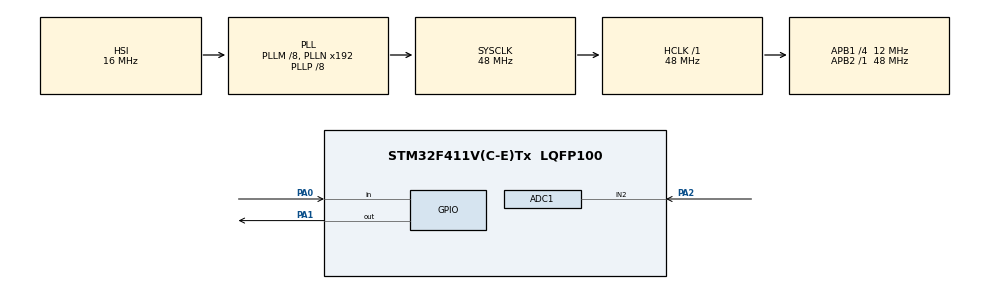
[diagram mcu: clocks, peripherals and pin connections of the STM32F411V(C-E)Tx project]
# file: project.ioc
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ADC1.Channel-0\#ChannelRegularConversion=ADC_CHANNEL_2
ADC1.ContinuousConvMode=ENABLE
ADC1.NbrOfConversionFlag=1
ADC1.Rank-0\#ChannelRegularConversion=1
ADC1.SamplingTime-0\#ChannelRegularConversion=ADC_SAMPLETIME_3CYCLES
ADC1.master=1
Mcu.Family=STM32F4
Mcu.Name=STM32F411V(C-E)Tx
Mcu.Package=LQFP100
NVIC.PriorityGroup=NVIC_PRIORITYGROUP_0
PA0-WKUP.Signal=GPIO_Input
PA1.Signal=GPIO_Output
PA2.Signal=ADCx_IN2
ProjectManager.HeapSize=0x200
ProjectManager.StackSize=0x400
ProjectManager.TargetToolchain=STM32CubeIDE
RCC.48MHZClocksFreq_Value=48000000
RCC.AHBFreq_Value=48000000
RCC.APB1CLKDivider=RCC_HCLK_DIV4
RCC.APB1Freq_Value=12000000
RCC.APB1TimFreq_Value=24000000
RCC.APB2Freq_Value=48000000
RCC.APB2TimFreq_Value=48000000
RCC.CortexFreq_Value=48000000
RCC.HCLKFreq_Value=48000000
RCC.HSE_VALUE=8000000
RCC.HSI_VALUE=16000000
RCC.LSE_VALUE=32768
RCC.PLLI2SM=5
RCC.PLLI2SN=200
RCC.PLLM=8
RCC.PLLP=RCC_PLLP_DIV8
RCC.PLLQ=8
RCC.SYSCLKFreq_VALUE=48000000
RCC.SYSCLKSource=RCC_SYSCLKSOURCE_PLLCLK
RCC.VCOOutputFreq_Value=384000000
SH.ADCx_IN2.0=ADC1_IN2,IN2
board=STM32F411E-DISCO

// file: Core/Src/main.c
/* USER CODE BEGIN Header */
/**
  ******************************************************************************
  * @file           : main.c
  * @brief          : Control simple de láser con botón
  ******************************************************************************
  */
/* USER CODE END Header */
#include "main.h"

/* USER CODE BEGIN PV */
volatile uint8_t disparo=0; //estado de disparo
volatile uint32_t valor_adc=0; //valor detectado
volatile uint8_t detectado=0; //estado de deteccion

//variables para la conversion y para el acceso directo a memoria del ldr
ADC_HandleTypeDef hadc1;
DMA_HandleTypeDef hdma_adc1;

/* USER CODE END PV */

void SystemClock_Config(void);
static void MX_GPIO_Init(void);
static void MX_ADC1_Init(void);

/* USER CODE BEGIN 0 */
void HAL_GPIO_EXTI_Callback(uint16_t GPIO_Pin){
	if (GPIO_Pin == GPIO_PIN_0){
		if (HAL_GPIO_ReadPin(GPIOA, GPIO_PIN_0) == 1){
			disparo = 1;
	        HAL_GPIO_WritePin(GPIOA, GPIO_PIN_1, GPIO_PIN_SET);
	    }
	    else{
	    	disparo = 0;
	        HAL_GPIO_WritePin(GPIOA, GPIO_PIN_1, GPIO_PIN_RESET);
	    }
	}
}

//}

/* USER CODE END 0 */

int main(void)
{

  /* MCU Configuration--------------------------------------------------------*/

  /* Reset of all peripherals, Initializes the Flash interface and the Systick. */
  HAL_Init();

  /* Configure the system clock */
  SystemClock_Config();

  /* Initialize all configured peripherals */
  MX_GPIO_Init();
  MX_ADC1_Init();
  /* USER CODE BEGIN 2 */

  //arranco el ADC
  HAL_ADC_Start_DMA(&hadc1, (uint32_t*)&valor_adc, 1);
  /* USER CODE END 2 */

  /* Infinite loop */
  while (1)
  {

    /* USER CODE BEGIN 3 */
	  if (disparo == 1)
	  {

	      if (valor_adc > 1500)
	      {
	          detectado = 1;
	      }
	      else
	      {
	          detectado = 0;
	      }
	  }
	  else
	  {
	      detectado = 0;
	  }
  /* USER CODE END 3 */
  }
}

void SystemClock_Config(void)
{
  RCC_OscInitTypeDef RCC_OscInitStruct = {0};
  RCC_ClkInitTypeDef RCC_ClkInitStruct = {0};

  /** Configure the main internal regulator output voltage
  */
  __HAL_RCC_PWR_CLK_ENABLE();
  __HAL_PWR_VOLTAGESCALING_CONFIG(PWR_REGULATOR_VOLTAGE_SCALE1);

  /** Initializes the RCC Oscillators according to the specified parameters
  * in the RCC_OscInitTypeDef structure.
  */
  RCC_OscInitStruct.OscillatorType = RCC_OSCILLATORTYPE_HSI;
  RCC_OscInitStruct.HSIState = RCC_HSI_ON;
  RCC_OscInitStruct.HSICalibrationValue = RCC_HSICALIBRATION_DEFAULT;
  RCC_OscInitStruct.PLL.PLLState = RCC_PLL_ON;
  RCC_OscInitStruct.PLL.PLLSource = RCC_PLLSOURCE_HSI;
  RCC_OscInitStruct.PLL.PLLM = 8;
  RCC_OscInitStruct.PLL.PLLN = 192;
  RCC_OscInitStruct.PLL.PLLP = RCC_PLLP_DIV8;
  RCC_OscInitStruct.PLL.PLLQ = 8;
  if (HAL_RCC_OscConfig(&RCC_OscInitStruct) != HAL_OK)
  {
    Error_Handler();
  }

  /** Initializes the CPU, AHB and APB buses clocks
  */
  RCC_ClkInitStruct.ClockType = RCC_CLOCKTYPE_HCLK|RCC_CLOCKTYPE_SYSCLK
                              |RCC_CLOCKTYPE_PCLK1|RCC_CLOCKTYPE_PCLK2;
  RCC_ClkInitStruct.SYSCLKSource = RCC_SYSCLKSOURCE_PLLCLK;
  RCC_ClkInitStruct.AHBCLKDivider = RCC_SYSCLK_DIV1;
  RCC_ClkInitStruct.APB1CLKDivider = RCC_HCLK_DIV4;
  RCC_ClkInitStruct.APB2CLKDivider = RCC_HCLK_DIV1;

  if (HAL_RCC_ClockConfig(&RCC_ClkInitStruct, FLASH_LATENCY_1) != HAL_OK)
  {
    Error_Handler();
  }
}

static void MX_ADC1_Init(void)
{

  ADC_ChannelConfTypeDef sConfig = {0};

  /* USER CODE BEGIN ADC1_Init 1 */
  __HAL_RCC_ADC1_CLK_ENABLE();
  __HAL_RCC_DMA2_CLK_ENABLE();

  /* USER CODE END ADC1_Init 1 */

  /** Configure the global features of the ADC (Clock, Resolution, Data Alignment and number of conversion)
  */
  hadc1.Instance = ADC1;
  hadc1.Init.ClockPrescaler = ADC_CLOCK_SYNC_PCLK_DIV4;
  hadc1.Init.Resolution = ADC_RESOLUTION_12B;
  hadc1.Init.ScanConvMode = DISABLE;
  hadc1.Init.ContinuousConvMode = ENABLE;
  hadc1.Init.DiscontinuousConvMode = DISABLE;
  hadc1.Init.ExternalTrigConvEdge = ADC_EXTERNALTRIGCONVEDGE_NONE;
  hadc1.Init.ExternalTrigConv = ADC_SOFTWARE_START;
  hadc1.Init.DataAlign = ADC_DATAALIGN_RIGHT;
  hadc1.Init.NbrOfConversion = 1;
  hadc1.Init.DMAContinuousRequests = ENABLE;
  hadc1.Init.EOCSelection = ADC_EOC_SINGLE_CONV;
  if (HAL_ADC_Init(&hadc1) != HAL_OK)
  {
    Error_Handler();
  }

  //añado esto para el dma
  hdma_adc1.Instance = DMA2_Stream0; // Verificar según tu modelo de STM32
  hdma_adc1.Init.Channel = DMA_CHANNEL_0;
  hdma_adc1.Init.Direction = DMA_PERIPH_TO_MEMORY;
  hdma_adc1.Init.PeriphInc = DMA_PINC_DISABLE;
  hdma_adc1.Init.MemInc = DMA_MINC_ENABLE;
  hdma_adc1.Init.PeriphDataAlignment = DMA_PDATAALIGN_WORD;
  hdma_adc1.Init.MemDataAlignment = DMA_MDATAALIGN_WORD;
  hdma_adc1.Init.Mode = DMA_CIRCULAR;
  hdma_adc1.Init.Priority = DMA_PRIORITY_LOW;

  HAL_DMA_Init(&hdma_adc1);

  __HAL_LINKDMA(&hadc1, DMA_Handle, hdma_adc1);

	  /** Configure for the selected ADC regular channel its corresponding rank in the sequencer and its sample time.
	  */
  sConfig.Channel = ADC_CHANNEL_2;
  sConfig.Rank = 1;
  sConfig.SamplingTime = ADC_SAMPLETIME_15CYCLES;
  if (HAL_ADC_ConfigChannel(&hadc1, &sConfig) != HAL_OK)
  {
    Error_Handler();
  }

}

static void MX_GPIO_Init(void)
{
  GPIO_InitTypeDef GPIO_InitStruct = {0};

  /* GPIO Ports Clock Enable */
  __HAL_RCC_GPIOA_CLK_ENABLE();
  __HAL_RCC_SYSCFG_CLK_ENABLE();

  /*Configure GPIO pin Output Level */
  HAL_GPIO_WritePin(GPIOA, GPIO_PIN_1, GPIO_PIN_RESET);

  /*Configure GPIO pin : PA0 */
  GPIO_InitStruct.Pin = GPIO_PIN_0;
  GPIO_InitStruct.Mode = GPIO_MODE_IT_RISING_FALLING;
  GPIO_InitStruct.Pull = GPIO_NOPULL;
  HAL_GPIO_Init(GPIOA, &GPIO_InitStruct);

  HAL_NVIC_SetPriority(EXTI0_IRQn, 0, 0);
  HAL_NVIC_EnableIRQ(EXTI0_IRQn);

  /*Configure GPIO pin : PA1 */
  GPIO_InitStruct.Pin = GPIO_PIN_1;
  GPIO_InitStruct.Mode = GPIO_MODE_OUTPUT_PP;
  GPIO_InitStruct.Pull = GPIO_NOPULL;
  GPIO_InitStruct.Speed = GPIO_SPEED_FREQ_LOW;
  HAL_GPIO_Init(GPIOA, &GPIO_InitStruct);

  /*Configure GPIO pin : PA2 */
  GPIO_InitStruct.Pin = GPIO_PIN_2;
  GPIO_InitStruct.Mode = GPIO_MODE_ANALOG;
  GPIO_InitStruct.Pull = GPIO_NOPULL;
  HAL_GPIO_Init(GPIOA, &GPIO_InitStruct);

}

void Error_Handler(void)
{
  __disable_irq();
  while (1)
  {
  }
}
